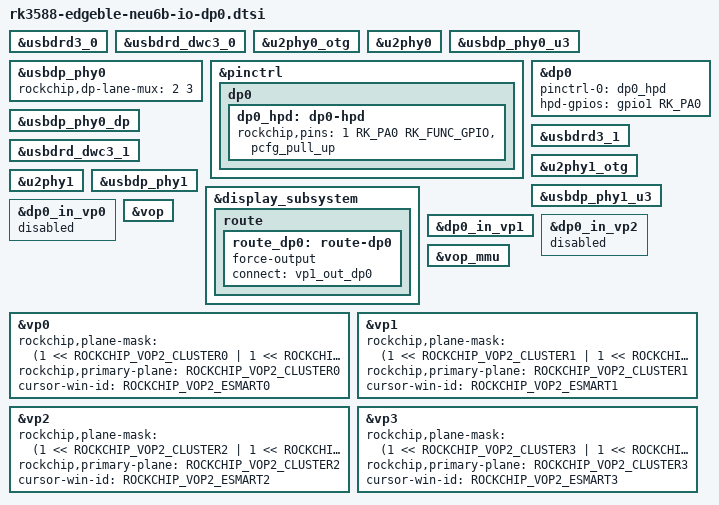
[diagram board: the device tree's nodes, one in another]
// SPDX-License-Identifier: (GPL-2.0+ OR MIT)
/*
 * Copyright (c) 2023 Edgeble AI Technologies Pvt. Ltd.
 */

&usbdrd3_0 {
	status = "okay";
};

/* OTG, set dr_mode = "host"; for host */
&usbdrd_dwc3_0 {
	status = "okay";
};

&u2phy0_otg {
	status = "okay";
};

&u2phy0 {
	status = "okay";
};

&usbdp_phy0_u3 {
	status = "okay";
};

&usbdp_phy0 {
	status = "okay";
};

/* DP0 */
&pinctrl {
	dp0 {
		dp0_hpd: dp0-hpd {
			rockchip,pins = <1 RK_PA0 RK_FUNC_GPIO &pcfg_pull_up>;
		};
	};
};

&dp0 {
	status = "okay";
	pinctrl-names = "default";
	pinctrl-0 = <&dp0_hpd>;
	hpd-gpios = <&gpio1 RK_PA0 GPIO_ACTIVE_HIGH>; /* DP1_HPDIN_M0 */
};

&usbdp_phy0_dp {
	status = "okay";
};

&usbdp_phy0 {
	status = "okay";
	rockchip,dp-lane-mux = < 2 3 >;
};

&usbdrd3_1 {
	status = "okay";
};

&usbdrd_dwc3_1 {
	status = "okay";
};

&u2phy1_otg {
	status = "okay";
};

&u2phy1 {
	status = "okay";
};

&usbdp_phy1_u3 {
	status = "okay";
};

&usbdp_phy1 {
	status = "okay";
};

&display_subsystem {
	route {
		route_dp0: route-dp0 {
			status = "okay";
			force-output;
			connect = <&vp1_out_dp0>;
		};
	};
};

&dp0_in_vp0 {
	status = "disabled";
};

&dp0_in_vp1 {
	status = "okay";
};

&dp0_in_vp2 {
	status = "disabled";
};

&vop {
	status = "okay";
};

&vop_mmu {
	status = "okay";
};

/* vp0 & vp1 splice for 8K output */
&vp0 {
	rockchip,plane-mask = <(1 << ROCKCHIP_VOP2_CLUSTER0 | 1 << ROCKCHIP_VOP2_ESMART0)>;
	rockchip,primary-plane = <ROCKCHIP_VOP2_CLUSTER0>;
	cursor-win-id = <ROCKCHIP_VOP2_ESMART0>;
};

&vp1 {
	rockchip,plane-mask = <(1 << ROCKCHIP_VOP2_CLUSTER1 | 1 << ROCKCHIP_VOP2_ESMART1)>;
	rockchip,primary-plane = <ROCKCHIP_VOP2_CLUSTER1>;
	cursor-win-id = <ROCKCHIP_VOP2_ESMART1>;
};

&vp2 {
	rockchip,plane-mask = <(1 << ROCKCHIP_VOP2_CLUSTER2 | 1 << ROCKCHIP_VOP2_ESMART2)>;
	rockchip,primary-plane = <ROCKCHIP_VOP2_CLUSTER2>;
	cursor-win-id = <ROCKCHIP_VOP2_ESMART2>;
};

&vp3 {
	rockchip,plane-mask = <(1 << ROCKCHIP_VOP2_CLUSTER3 | 1 << ROCKCHIP_VOP2_ESMART3)>;
	rockchip,primary-plane = <ROCKCHIP_VOP2_CLUSTER3>;
	cursor-win-id = <ROCKCHIP_VOP2_ESMART3>;
};
